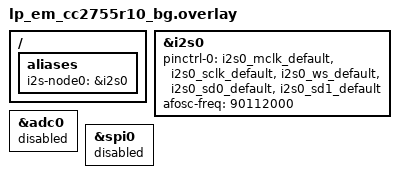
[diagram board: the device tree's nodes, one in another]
/*
 * Copyright (c) 2026 Texas Instruments Incorporated
 *
 * SPDX-License-Identifier: Apache-2.0
 */

/*
 * I2S speed test overlay for lp_em_cc2755r10_bg
 *
 * DIR_BOTH loopback test configuration:
 *   DIO6  = MCLK  (optional master clock)
 *   DIO17 = SCLK  (BCLK, bit clock)
 *   DIO18 = WS    (WCLK, word/frame clock)
 *   DIO19 = SD0   (TX data output)
 *   DIO30 = SD1   (RX data input)
 *
 * GPIO loopback wiring: connect DIO19 (SD0) to DIO30 (SD1)
 */

/ {
	aliases {
		i2s-node0 = &i2s0;
	};
};

&i2s0 {
	status = "okay";
	pinctrl-0 = <&i2s0_mclk_default &i2s0_sclk_default
		     &i2s0_ws_default &i2s0_sd0_default &i2s0_sd1_default>;
	pinctrl-names = "default";

	/* AFOSC for 44 kHz sample rate (i2s_speed uses FRAME_CLK_FREQ = 44000)
	 * 44 kHz family formula: afosc = 44000 x 2048 = 90,112,000 Hz (90.112 MHz)
	 * This allows exact division: 90,112,000 / 2048 = 44000 Hz
	 */
	afosc-freq = <90112000>;
};

/* ADC channels 6, 7, 8 and 9 share DIO19, DIO18, DIO17 and DIO30 with I2S0 */
&adc0 {
	status = "disabled";
};

/* DIO19 is the SPI0 chip select of the on-board flash, shared with SD0 */
&spi0 {
	status = "disabled";
};
